VERSION ""

NS_ :

BS_:

BU_: MC_STEPPER LISTENER COMMANDER REQUESTER

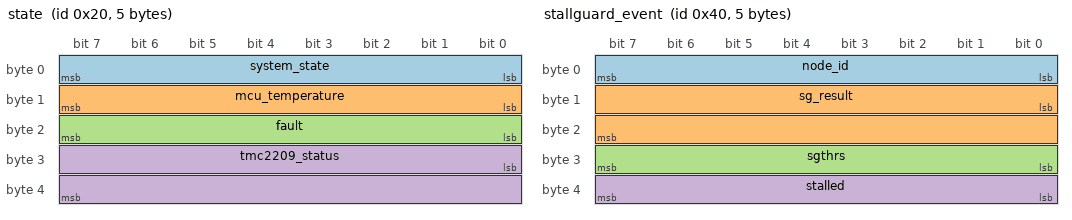
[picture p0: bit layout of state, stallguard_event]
BO_ 32 state: 5 MC_STEPPER
 SG_ system_state : 0|8@1+ (1,0) [0|255] ""  LISTENER
 SG_ mcu_temperature : 8|8@1+ (1,-40) [-40|215] "degC"  LISTENER
 SG_ fault : 16|8@1+ (1,0) [0|255] ""  LISTENER
 SG_ tmc2209_status : 24|16@1+ (1,0) [0|65535] ""  LISTENER

BO_ 64 stallguard_event: 5 MC_STEPPER
 SG_ node_id : 0|8@1+ (1,0) [0|255] ""  LISTENER
 SG_ sg_result : 8|16@1+ (1,0) [0|1023] ""  LISTENER
 SG_ sgthrs : 24|8@1+ (1,0) [0|255] ""  LISTENER
 SG_ stalled : 32|8@1+ (1,0) [0|1] ""  LISTENER

BO_ 96 command_stepper: 6 COMMANDER
 SG_ node_id : 0|8@1+ (1,0) [0|255] ""  MC_STEPPER
 SG_ control_mode M : 8|3@1+ (1,0) [0|7] ""  MC_STEPPER
 SG_ enable : 11|1@1+ (1,0) [0|1] ""  MC_STEPPER
 SG_ clear_faults : 12|1@1+ (1,0) [0|1] ""  MC_STEPPER
 SG_ reserved0 : 13|3@1+ (1,0) [0|7] ""  MC_STEPPER
 SG_ target_position_abs m1 : 16|32@1- (0.001,0) [-2147483.648|2147483.647] "rad"  MC_STEPPER
 SG_ target_velocity m2 : 16|32@1- (0.001,0) [-2147483.648|2147483.647] "rad/s"  MC_STEPPER
 SG_ target_position_rel m3 : 16|32@1- (0.001,0) [-2147483.648|2147483.647] "rad"  MC_STEPPER
 SG_ target_position_ol m4 : 16|32@1- (0.001,0) [-2147483.648|2147483.647] "rad"  MC_STEPPER

BO_ 128 command_stepper_zero: 1 COMMANDER
 SG_ node_id : 0|8@1+ (1,0) [0|255] ""  MC_STEPPER

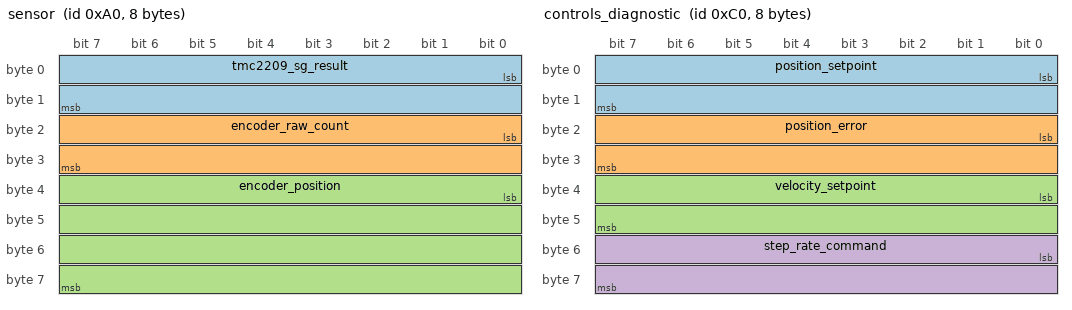
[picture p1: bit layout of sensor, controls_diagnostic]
BO_ 160 sensor: 8 MC_STEPPER
 SG_ tmc2209_sg_result : 0|16@1+ (1,0) [0|510] "count"  LISTENER
 SG_ encoder_raw_count : 16|16@1- (1,0) [-32768|32767] "count"  LISTENER
 SG_ encoder_position : 32|32@1- (0.001,0) [-2147483.648|2147483.647] "rad"  LISTENER

BO_ 192 controls_diagnostic: 8 MC_STEPPER
 SG_ position_setpoint : 0|16@1- (0.001,0) [-32.768|32.767] "rad"  LISTENER
 SG_ position_error : 16|16@1- (0.0001,0) [-3.2768|3.2767] "rad"  LISTENER
 SG_ velocity_setpoint : 32|16@1- (0.001,0) [-32.768|32.767] "rad/s"  LISTENER
 SG_ step_rate_command : 48|16@1- (1,0) [-32768|32767] "steps/s"  LISTENER

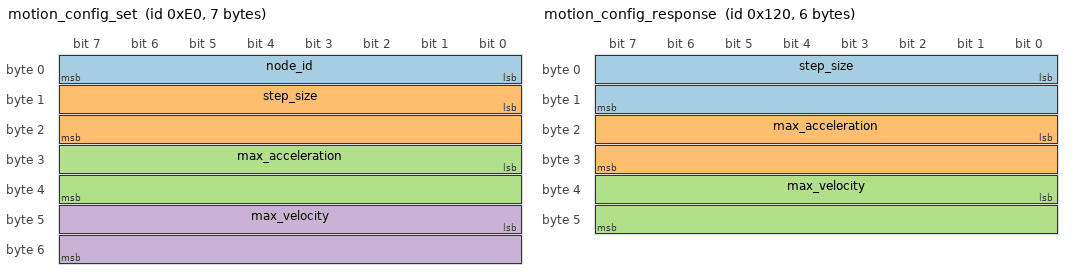
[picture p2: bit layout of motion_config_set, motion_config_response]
BO_ 224 motion_config_set: 7 COMMANDER
 SG_ node_id : 0|8@1+ (1,0) [0|255] ""  MC_STEPPER
 SG_ step_size : 8|16@1+ (1,0) [0|256] ""  MC_STEPPER
 SG_ max_acceleration : 24|16@1+ (0.1,0) [0|6553.5] "rad/s2"  MC_STEPPER
 SG_ max_velocity : 40|16@1+ (0.001,0) [0|65.535] "rad/s"  MC_STEPPER

BO_ 256 motion_config_get: 1 REQUESTER
 SG_ node_id : 0|8@1+ (1,0) [0|255] ""  MC_STEPPER

BO_ 288 motion_config_response: 6 MC_STEPPER
 SG_ step_size : 0|16@1+ (1,0) [0|256] ""  REQUESTER
 SG_ max_acceleration : 16|16@1+ (0.1,0) [0|6553.5] "rad/s2"  REQUESTER
 SG_ max_velocity : 32|16@1+ (0.001,0) [0|65.535] "rad/s"  REQUESTER

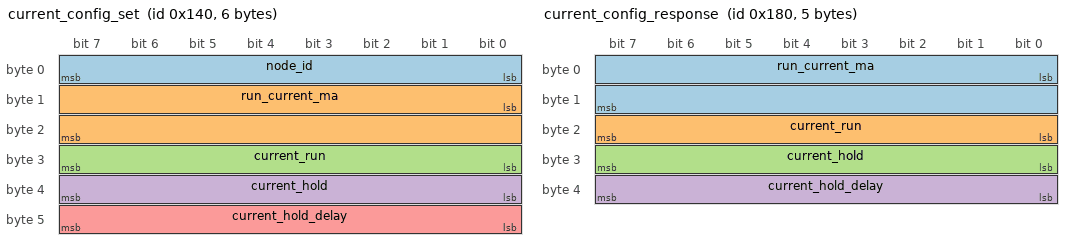
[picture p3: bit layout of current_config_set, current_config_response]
BO_ 320 current_config_set: 6 COMMANDER
 SG_ node_id : 0|8@1+ (1,0) [0|255] ""  MC_STEPPER
 SG_ run_current_ma : 8|16@1+ (1,0) [0|3000] "mA"  MC_STEPPER
 SG_ current_run : 24|8@1+ (1,0) [0|31] ""  MC_STEPPER
 SG_ current_hold : 32|8@1+ (1,0) [0|31] ""  MC_STEPPER
 SG_ current_hold_delay : 40|8@1+ (1,0) [0|15] ""  MC_STEPPER

BO_ 352 current_config_get: 1 REQUESTER
 SG_ node_id : 0|8@1+ (1,0) [0|255] ""  MC_STEPPER

BO_ 384 current_config_response: 5 MC_STEPPER
 SG_ run_current_ma : 0|16@1+ (1,0) [0|3000] "mA"  REQUESTER
 SG_ current_run : 16|8@1+ (1,0) [0|31] ""  REQUESTER
 SG_ current_hold : 24|8@1+ (1,0) [0|31] ""  REQUESTER
 SG_ current_hold_delay : 32|8@1+ (1,0) [0|15] ""  REQUESTER

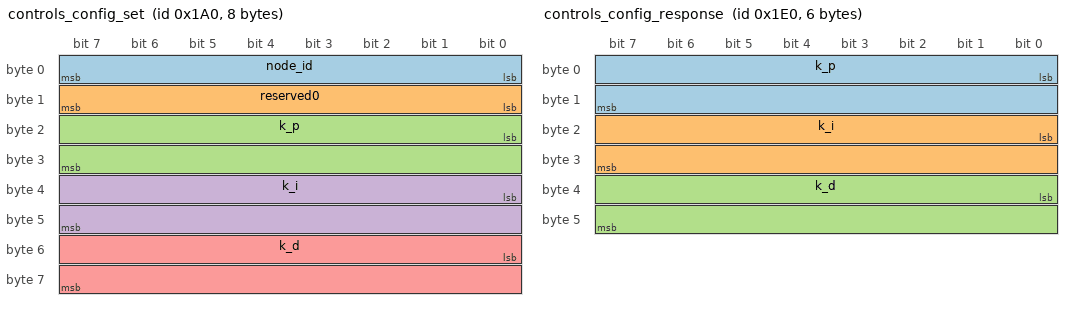
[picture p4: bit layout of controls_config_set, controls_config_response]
BO_ 416 controls_config_set: 8 COMMANDER
 SG_ node_id : 0|8@1+ (1,0) [0|255] ""  MC_STEPPER
 SG_ reserved0 : 8|8@1+ (1,0) [0|255] ""  MC_STEPPER
 SG_ k_p : 16|16@1+ (0.001,0) [0|65.535] ""  MC_STEPPER
 SG_ k_i : 32|16@1+ (0.001,0) [0|65.535] ""  MC_STEPPER
 SG_ k_d : 48|16@1+ (0.001,0) [0|65.535] ""  MC_STEPPER

BO_ 448 controls_config_get: 1 REQUESTER
 SG_ node_id : 0|8@1+ (1,0) [0|255] ""  MC_STEPPER

BO_ 480 controls_config_response: 6 MC_STEPPER
 SG_ k_p : 0|16@1+ (0.001,0) [0|65.535] ""  REQUESTER
 SG_ k_i : 16|16@1+ (0.001,0) [0|65.535] ""  REQUESTER
 SG_ k_d : 32|16@1+ (0.001,0) [0|65.535] ""  REQUESTER

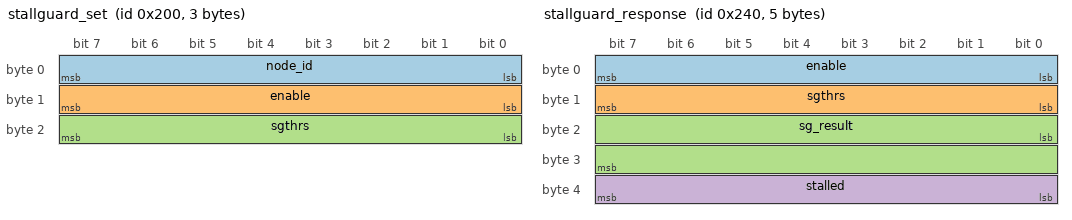
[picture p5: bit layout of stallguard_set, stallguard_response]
BO_ 512 stallguard_set: 3 COMMANDER
 SG_ node_id : 0|8@1+ (1,0) [0|255] ""  MC_STEPPER
 SG_ enable : 8|8@1+ (1,0) [0|1] ""  MC_STEPPER
 SG_ sgthrs : 16|8@1+ (1,0) [0|255] ""  MC_STEPPER

BO_ 544 stallguard_get: 1 REQUESTER
 SG_ node_id : 0|8@1+ (1,0) [0|255] ""  MC_STEPPER

BO_ 576 stallguard_response: 5 MC_STEPPER
 SG_ enable : 0|8@1+ (1,0) [0|1] ""  REQUESTER
 SG_ sgthrs : 8|8@1+ (1,0) [0|255] ""  REQUESTER
 SG_ sg_result : 16|16@1+ (1,0) [0|1023] ""  REQUESTER
 SG_ stalled : 32|8@1+ (1,0) [0|1] ""  REQUESTER

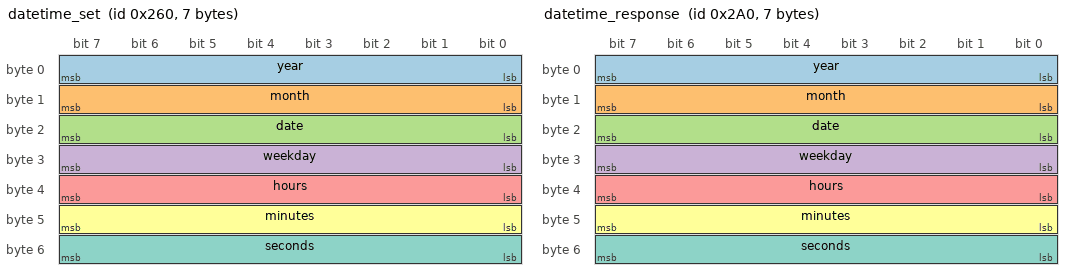
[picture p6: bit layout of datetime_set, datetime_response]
BO_ 608 datetime_set: 7 COMMANDER
 SG_ year : 0|8@1+ (1,0) [0|99] "year"  MC_STEPPER
 SG_ month : 8|8@1+ (1,0) [1|12] "month"  MC_STEPPER
 SG_ date : 16|8@1+ (1,0) [1|31] "day"  MC_STEPPER
 SG_ weekday : 24|8@1+ (1,0) [1|7] "weekday"  MC_STEPPER
 SG_ hours : 32|8@1+ (1,0) [0|23] "hour"  MC_STEPPER
 SG_ minutes : 40|8@1+ (1,0) [0|59] "min"  MC_STEPPER
 SG_ seconds : 48|8@1+ (1,0) [0|59] "sec"  MC_STEPPER

BO_ 640 datetime_get: 0 REQUESTER

BO_ 672 datetime_response: 7 MC_STEPPER
 SG_ year : 0|8@1+ (1,0) [0|99] "year"  REQUESTER
 SG_ month : 8|8@1+ (1,0) [1|12] "month"  REQUESTER
 SG_ date : 16|8@1+ (1,0) [1|31] "day"  REQUESTER
 SG_ weekday : 24|8@1+ (1,0) [1|7] "weekday"  REQUESTER
 SG_ hours : 32|8@1+ (1,0) [0|23] "hour"  REQUESTER
 SG_ minutes : 40|8@1+ (1,0) [0|59] "min"  REQUESTER
 SG_ seconds : 48|8@1+ (1,0) [0|59] "sec"  REQUESTER

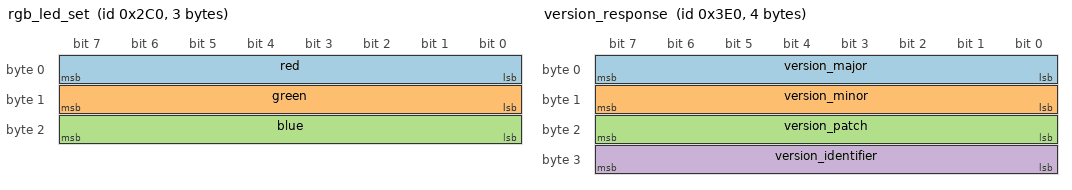
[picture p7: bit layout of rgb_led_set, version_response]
BO_ 704 rgb_led_set: 3 REQUESTER
 SG_ red : 0|8@1+ (1,0) [0|255] ""  MC_STEPPER
 SG_ green : 8|8@1+ (1,0) [0|255] ""  MC_STEPPER
 SG_ blue : 16|8@1+ (1,0) [0|255] ""  MC_STEPPER

BO_ 960 version_get: 0 REQUESTER

BO_ 992 version_response: 4 MC_STEPPER
 SG_ version_major : 0|8@1+ (1,0) [0|255] "major"  REQUESTER
 SG_ version_minor : 8|8@1+ (1,0) [0|255] "minor"  REQUESTER
 SG_ version_patch : 16|8@1+ (1,0) [0|255] "patch"  REQUESTER
 SG_ version_identifier : 24|8@1+ (1,0) [0|255] "ascii"  REQUESTER

BA_DEF_  "BusType" STRING ;
BA_DEF_DEF_  "BusType" "CAN";
